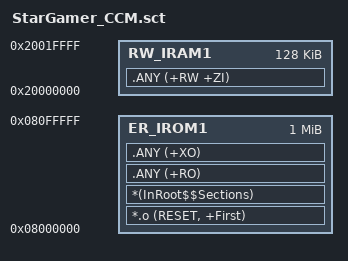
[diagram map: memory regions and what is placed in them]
; *************************************************************
; Star Gamer scatter file.
; *************************************************************

LR_IROM1 0x08000000 0x00100000  {
  ER_IROM1 0x08000000 0x00100000  {
   *.o (RESET, +First)
   *(InRoot$$Sections)
   .ANY (+RO)
   .ANY (+XO)
  }
  RW_IRAM1 0x20000000 0x00020000  {
   .ANY (+RW +ZI)
  }
}
